# ICONT1_SBH_ICONT register map
Vendor: Texas Instruments
Peripheral module from a debugger description file (folder DRA74xP_75xP_76xP_77xP).
Registers are 32-bit, access per field, reset 0x0 unless marked. A register's access mark holds for its fields unless they carry their own. Offsets are as the file gives them; lines under a group give offsets from that group; [hi:lo] are bit positions; {n}, {i} and the like mark numbered series; 'fields as' and 'values as' point back to an identical list; <NAME> marks a mode.

## ICONT1_SBH_ICONT
0x00 ICONT_SBH_CTRL reset 0x1 — SYNCBOX Handler control register
  [0] BYPASS rw — Control SYNCBOX bypass mode. This bit defines if SYNCBOX is used to synchronize Task between the different HWAs.
    0=SB_(SYNCBOX_0 (SB Bypass mode disabled. (SYNCBOX are used)); 1=SB_(SYNCBOX_1 (SB Bypass mode enabled. (SYNCBOX are not used).)
0x04 ICONT_SBH_ATLR ro — Activation Task List register. It logs reference of the task interrupting CPU. When bit field x of TX_0 field is 1, Task x has generated an interrupt to the CPU. Bit field n of this register is cleared when writing 1 in bitfiled x of register.
  [5:0] TX_0 — Task x to 0 (x=SYNCBOX_NB_TASK-1)
0x08 ICONT_SBH_ACK access not given — Acknowledge Task register. Task x is automatically acknowledged on writing 1 into bit field x of this register. Register is automatically cleared.
  [5:0] TX_0 — Task x to 0 (x=SYNCBOX_NB_TASK-1) (access W W1toClr)
0x0C ICONT_SBH_EOT access not given — End Of Task register. SBH notify to the SB that Task x is ended on writing 1 to this register. Register is automatically cleared.
  [5:0] TX_0 — Task x to 0 (x=SYNCBOX_NB_TASK-1) (access W W1toClr)
0x20 ICONT_SBH_IRQ_EOI — End Of Interrupt number specification
  [0] LINE_NUMBER rw — Software End Of Interrupt (EOI) control. Write number of interrupt output.
    0=EOI0 (EOI for interrupt output line #0 (end of transfer interrupt for SBH bypass mode)); 0=EOI1 (Reads always 0 (no EOI memory)); 1=EOI1 (EOI for interrupt output line #1 (error interrupt))
0x24 ICONT_SBH_IRQSTATUS_RAW_0 access not given — Per-event raw interrupt status vector, line #0 (end of transfer). Raw status is set even if event is not enabled. Write 1 to set the (raw) status, mostly for debug.
  [0] VDMAG_END — settable raw status for end of transfer interrupt event (access RW W1toSet)
    0=No_action; 0=No_event_pending; 1=Event_pending; 1=Set_event_(debug)
0x28 ICONT_SBH_IRQSTATUS_0 access not given — Per-event 'enabled' interrupt status vector, line #0 (end of transfer). Enabled status is not set unless event is enabled. Write 1 to clear the status after interrupt has been serviced (raw status gets cleared, that is, even if not enabled).
  [0] VDMAG_END — clearable, enabled status for end of transfer interrupt event (access RW W1toClr)
    0=No_action; 0=No_(enabled)_event_pending; 1=Event_pending; 1=Clear_(raw)_event
0x2C ICONT_SBH_IRQENABLE_SET_0 access not given — Per-event interrupt enable bit vector, line #0 (end of transfer). Write 1 to set (enable interrupt). Readout equal to corresponding _CLR register.
  [0] VDMAG_END — enable for end of transfer interrupt event (access RW W1toSet)
    0=No_action; 0=Interrupt_disabled_(masked); 1=Interrupt_enabled; 1=Enable_interrupt
0x30 ICONT_SBH_IRQENABLE_CLR_0 access not given — Per-event interrupt enable bit vector, line #0 (end of transfer). Write 1 to clear (disable interrupt). Readout equal to corresponding _SET register.
  [0] VDMAG_END — enable for end of transfer interrupt event (access RW W1toClr)
    0=No_action; 0=Interrupt_disabled_(masked); 1=Interrupt_enabled; 1=Disable_interrupt
0x34 ICONT_SBH_IRQSTATUS_RAW_1 access not given — Per-event raw interrupt status vector, line #0 (error). Raw status is set even if event is not enabled. Write 1 to set the (raw) status, mostly for debug.
  [0] SBH_ERR — settable raw status for SBH error event (access RW W1toSet)
    values as ICONT_SBH_IRQSTATUS_RAW_0.VDMAG_END
0x38 ICONT_SBH_IRQSTATUS_1 access not given — Per-event 'enabled' interrupt status vector, line #1 (error). Enabled status is not set unless event is enabled. Write 1 to clear the status after interrupt has been serviced (raw status gets cleared, that is, even if not enabled).
  [0] SBH_ERR — clearable, enabled status for SBH error event (access RW W1toClr)
    values as ICONT_SBH_IRQSTATUS_0.VDMAG_END
0x3C ICONT_SBH_IRQENABLE_SET_1 access not given — Per-event interrupt enable bit vector, line #1 (error). Write 1 to set (enable interrupt). Readout equal to corresponding _CLR register.
  [0] SBH_ERR — enable for SBH error event (access RW W1toSet)
    values as ICONT_SBH_IRQENABLE_SET_0.VDMAG_END
0x40 ICONT_SBH_IRQENABLE_CLR_1 access not given — Per-event interrupt enable bit vector, line #1 (error). Write 1 to clear (disable interrupt). Readout equal to corresponding _SET register.
  [0] SBH_ERR — enable for SBH error event (access RW W1toClr)
    values as ICONT_SBH_IRQENABLE_CLR_0.VDMAG_END
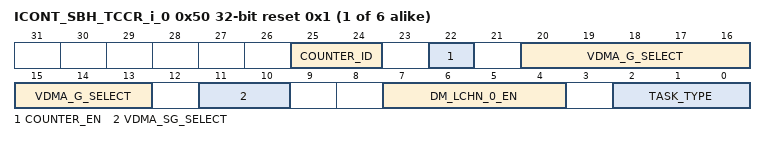
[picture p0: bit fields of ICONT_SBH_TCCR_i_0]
{0x50+4i} ICONT_SBH_TCCR_i_{i} reset 0x1 (i=0..5) — Task n Configuration Control Register
  [25:24] COUNTER_ID rw — Counter Identifier
  [22] COUNTER_EN rw — Counter Enable Bit
  [20:13] VDMA_G_SELECT rw — DMA_IVA Group Selector
  [11:10] VDMA_SG_SELECT rw — DMA_IVA Super Group Enable
    0=DMA_IVA_0 (Enabled DMA_IVA Groups are in the range of 0 to 7); 1=DMA_IVA_1 (Enabled DMA_IVA Groups are in the range of 8 to 15); 2=DMA_IVA_2 (Enabled DMA_IVA Groups are in the range of 16 to 23); 3=DMA_IVA_3 (Enabled DMA_IVA Groups are in the range of 24 to 31)
  [7:4] DM_LCHN_0_EN rw — Enable Data Mover Logical channel n to 0 (n=NB_DM_LCH-1)
  [2:0] TASK_TYPE rw
    0=Immediate_Task_End; 1=CPU_only_activated; 2=DMA_IVA_only_activated; 3=DM_then_CPU_activated; 4=DM_then_DMA_IVA_only_activated; 5=CPU_then_DMA_IVA_only_activated; 6=CPU_then_DM_activated; 7=CPU_then_DM_then_DMA_IVA_activated
{0x90+4i} ICONT_SBH_COUNTER_j_{i} (i=0..3) — Initialization value of SYNCBOX Handler Counter n
  [7:0] COUNT rw — Value to preload on counter
{0xB0+4i} ICONT_SBH_DMLCH_CFG_j_{i} (i=0..3) — This register defines which DMA_IVA group is associated to the Data Mover Logical Chanel n.
  [4:0] VDMA_GROUP_ID rw — DMA_IVA group identifier.
0xD0 ICONT_SBH_BYP_VDMAG_START wo — SYNCBOX Bypass mode DMA_IVA group Start register. Register is cleared when ICONT_SBHCTRL.BYPASS bit is writen to 1. Writing to this register is allowed only when ICONT_SBHCTRL.BYPASS bit is 1. Writing 1 into bitfiel n will START DMA_IVA group n. This register is cleared when ICONT_SBHCTRL.BYPASS bit is writen to 1.
  [31:0] VDMAG31_0 — Start DMA_IVA Group
0xD4 ICONT_SBH_BYP_VDMAG_END ro — SYNCBOX Bypass mode DMA_IVA group End register status. This register is cleared when ICONT_SBHCTRL.BYPASS bit is writen to 1. It is updated every time a DMA_IVA group is completed, that is, on DMA_IVA End of Group detection, only if ICONT_SBHCTRL.BYPASS bit is 1.
  [31:0] VDMAG31_0 — DMA_IVA Group is ended
